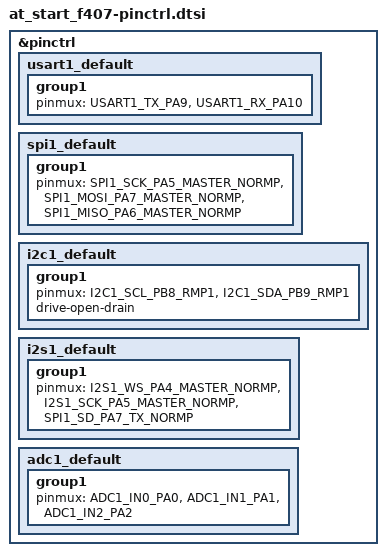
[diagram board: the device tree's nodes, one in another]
/*
 * Copyright (c) 2025, Maxjta
 * SPDX-License-Identifier: Apache-2.0
 */

#include <dt-bindings/pinctrl/at32f407v(g)xx-pinctrl.h>

&pinctrl {
	usart1_default: usart1_default {
		group1 {
			pinmux = <USART1_TX_PA9>, <USART1_RX_PA10>;
		};
	};
	spi1_default: spi1_default {
		group1 {
			pinmux = <SPI1_SCK_PA5_MASTER_NORMP>, <SPI1_MOSI_PA7_MASTER_NORMP>,
				 <SPI1_MISO_PA6_MASTER_NORMP>;
		};
	};
	i2c1_default: i2c1_default {
		group1 {
			pinmux = <I2C1_SCL_PB8_RMP1>, <I2C1_SDA_PB9_RMP1>;
			drive-open-drain;
		};
	};
	i2s1_default: i2s1_default {
		group1 {
			pinmux = <I2S1_WS_PA4_MASTER_NORMP>, <I2S1_SCK_PA5_MASTER_NORMP>,
				 <SPI1_SD_PA7_TX_NORMP>;
		};
	};
	adc1_default: adc1_default {
		group1 {
			pinmux = <ADC1_IN0_PA0>, <ADC1_IN1_PA1>, <ADC1_IN2_PA2>;
		};
	};
};
